# nrf9230_enga_application register map
Vendor: Nordic Semiconductor; Series: nRF92; File version: 1
CPU: CM33 r0p4, little endian, MPU, FPU, 3 interrupt priority bits, 480 interrupts, 4 SAU regions
Registers are 32-bit, read-write, reset 0x0 unless marked. A register's access mark holds for its fields unless they carry their own. Offsets are from the block's base; [hi:lo] are bit positions; lines under a group give offsets from that group; {n}, {i} and the like mark numbered series.

## GLOBAL_FICR_NS — Factory Information Configuration Registers
Base 0x0FFFE000
0x0C BLE group — Unspecified
  0x00 ADDRTYPE ro reset 0xFFFFFFFF — Device address type.
    [0] TYPE
      0=Public address; 1=Random address
  {0x4+4j} ADDR[{j}] (j=0..1) ro reset 0xFFFFFFFF — Description collection: 48 bit device address.
    [31:0] ADDR — Device address [n].
  {0xC+4j} ER[{j}] (j=0..3) ro reset 0xFFFFFFFF — Description collection: Encryption Root.
    [31:0] ER — Encryption root word [n].
  {0x1C+4j} IR[{j}] (j=0..3) ro reset 0xFFFFFFFF — Description collection: Identity Root.
    [31:0] IR — Identity root word [n].
0x50 INFO group — Device info
  0x00 CONFIGID ro reset 0xFFFFFFFF — Configuration identifier
    [15:0] HWID — Identification number for the HW
  0x04 PART ro reset 0xFFFFFFFF — Part code
    [31:0] PART
      0xFFFFFFFF=Unspecified
  0x08 VARIANT ro reset 0xFFFFFFFF — Part Variant, Hardware version and Production configuration
    [31:0] VARIANT — Part Variant, Hardware version and Production configuration, encoded as ASCII
      0xFFFFFFFF=Unspecified
  0x0C PACKAGE ro reset 0xFFFFFFFF — Package option
    [31:0] PACKAGE
      0xFFFFFFFF=Unspecified
  0x10 RAM ro reset 0xFFFFFFFF — RAM variant
    [31:0] RAM
      0xFFFFFFFF=Unspecified
  0x14 MRAM ro reset 0xFFFFFFFF — MRAM variant
    [31:0] MRAM
      0xFFFFFFFF=Unspecified
  0x18 CODEPAGESIZE ro reset 0x1000 — Code memory page size in bytes
    [31:0] CODEPAGESIZE
      0xFFFFFFFF=Unspecified
  0x1C CODESIZE ro reset 0x100 — Code memory size
    [31:0] CODESIZE — Code memory size in number of pages
      0xFFFFFFFF=Unspecified
  0x20 DEVICETYPE ro
    [31:0] DEVICETYPE
      0=Die (Device is an physical DIE); 0xFFFFFFFF=FPGA (Device is an FPGA)
0x80 SIPINFO group — SIP-specific device info
  0x00 PARTNO ro reset 0xFFFFFFFF — SIP part number
  {0x4+j} HWREVISION[{j}] (j=0..3) 8-bit ro reset 0xFF — Description collection: SIP hardware revision, encoded in ASCII, ex B0A or B1A
    [7:0] HWREVISION
  {0x8+j} VARIANT[{j}] (j=0..3) 8-bit ro reset 0xFF — Description collection: SIP VARIANT, encoded in ASCII, ex SIAA, SIBA or SICA
    [7:0] VARIANT
  0x0C PMICVERSION ro
    [31:0] PMICVERSION — PMIC version, incremental code
  {0x10+j} TESTSITE[{j}] (j=0..3) 8-bit ro — Description collection: Test site, in ascii
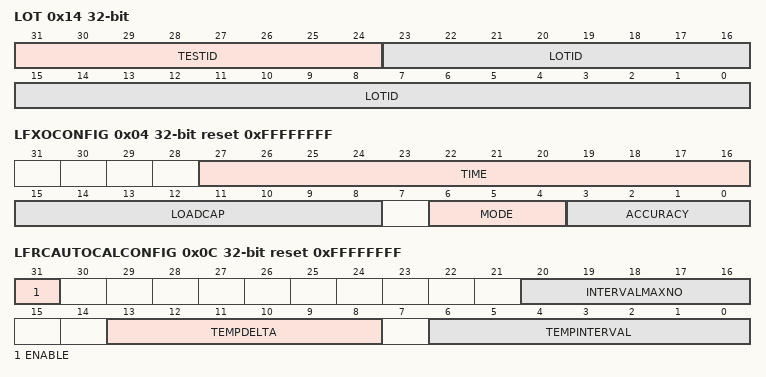
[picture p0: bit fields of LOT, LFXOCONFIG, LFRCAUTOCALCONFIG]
  0x14 LOT ro — Lot number + test index in hex format (number digits 0-9).
    [31:24] TESTID — Test ID in hex format
    [23:0] LOTID — Lot number in hex format
  {0x18+j} TESTPROGRAMID[{j}] (j=0..3) 8-bit ro — Description collection: Test program id, in ascii
  0x1C OSATPARTNO ro reset 0xFFFFFFFF — OSAT part number
  {0x20+j} HWBUILDVERSION[{j}] (j=0..3) 8-bit ro reset 0xFF — Description collection: OSAT production build version
  0x24 OVERRIDE group — Unspecified
    0x00 LFOSC group — Unspecified
      0x00 CONFIG reset 0xFFFFFFFF — LF oscillator configuration. Note. This configuration overrides corresponding LF oscillator configuration in BICR when set.
        [3:0] SRC — LF oscillator source.
          15=Unconfigured (LF oscillator source is unconfigured. Default will be used.); 0=LFXO (Use LFXO as source for the LF oscillator.); 1=LFRC (Use LFRC as source for the LF oscillator.); 2=LFLPRC (Use LFLPRC as source for the LF oscillator.); 3=Synth (Use LF Synth as source for the LF oscillator.)
      0x04 LFXOCONFIG reset 0xFFFFFFFF — LFXO configuration. Note. This configuration overrides corresponding LFXO configuration in BICR when set.
        [27:16] TIME — LFXO startup time in ms.
          0xFFF=Unconfigured (Startup time has not been configured.)
        [15:8] LOADCAP — Built-in load capacitors selection in 1 pF steps. Max. value 25 pF.
          255=Unconfigured (The built-in load capacitors is unconfigured. LFXO will not start unless LOADCAP is configured.); 0=External (Do not use the built-in load capacitors, only external capacitors will be used.)
        [6:4] MODE — LFXO mode. LFXO will not start unless MODE is configured.
          7=Unconfigured (The mode is unconfigured.); 0=Pierce (LFXO Pierce mode.); 1=PIXO (LFXO PIXO mode.); 2=ExtSine (LFXO in external sine wave mode.); 3=ExtSquare (LFXO in external square wave mode.)
        [3:0] ACCURACY — LFXO crystal or external signal accuracy.
          15=Unconfigured (The accuracy is unconfigured.); 0=500ppm (LFXO crystal or external signal has an accuracy of 500 ppm.); 1=250ppm (LFXO crystal or external signal has an accuracy of 250 ppm.); 2=150ppm (LFXO crystal or external signal has an accuracy of 150 ppm.); 3=100ppm (LFXO crystal or external signal has an accuracy of 100 ppm.); 4=75ppm (LFXO crystal or external signal has an accuracy of 75 ppm.); 5=50ppm (LFXO crystal or external signal has an accuracy of 50 ppm.); 6=30ppm (LFXO crystal or external signal has an accuracy of 30 ppm.); 7=20ppm (LFXO crystal or external signal has an accuracy of 20 ppm.)
      0x08 LFXOCAL reset 0xFFFFFFFF — LFXO calibration needed. Must be written to 0xFFFFFFFF after any modification of the LFXO board circuit, load capacitance, or crystal swap. Note. This configuration overrides corresponding LFXO calibration in BICR when set.
        [31:0] LFXOCAL — LFXO calibration needed. Must be written to 0xFFFFFFFF after any modification of the LFXO board circuit, load capacitance, or crystal swap.
          0xFFFFFFFF=Calibrate the LFXO at startup
      0x0C LFRCAUTOCALCONFIG reset 0xFFFFFFFF — LFRC autocalibration configuration. Note. This configuration overrides corresponding LFRC autocalibration configuration in BICR when set.
        [31] ENABLE — LFRC.AUTOCALCONFIG register enable.
          0=Enabled (LFRC.AUTOCALCONFIG register has been configured and can be used.); 1=Disabled (LFRC.AUTOCALCONFIG register has not been configured and cannot be used.)
        [20:16] INTERVALMAXNO — Maximum number of TEMPINTERVAL periods in between calibrations, independent of temperature changes.
        [13:8] TEMPDELTA — Temperature delta that should trigger a calibration in 0.25 degrees steps.
        [6:0] TEMPINTERVAL — Temperature measurement interval in 0.25 s steps.
    0x10 HFXO64M group — Unspecified
      0x00 CONFIG reset 0xFFFFFFFF — HFXO64M configuration. Note. This configuration overrides corresponding XO configuration in BICR when set.
        [2:0] MODE — HFXO64M mode.
          7=Unconfigured (The mode is unconfigured.); 0=Normal operating mode; 1=TCXO (TCXO/bypass mode); {v}=Crystal{v} (Reserved value) (v=2..6)
0x100 TRIM group — Unspecified
  0x244 GLOBAL group — Unspecified
    0x00 SAADC group — Unspecified
      0x00 CALVREF ro reset 0xFFFFFFFF — Trim value for GLOBAL.SAADC.CALVREF
        [31:0] VALUE — Trim value
      {0x4+4l} CALGAIN[{l}] (l=0..2) ro reset 0xFFFFFFFF — Description collection: Trim value for GLOBAL.SAADC.CALGAIN
        [31:0] VALUE — Trim value
      0x10 CALOFFSET ro reset 0xFFFFFFFF — Trim value for GLOBAL.SAADC.CALOFFSET
        [31:0] VALUE — Trim value
      {0x14+4l} LINCALCOEFF[{l}] (l=0..5) ro reset 0xFFFFFFFF — Description collection: Trim value for GLOBAL.SAADC.LINCALCOEFF
        [31:0] VALUE — Trim value
      0x2C CALIREF ro reset 0xFFFFFFFF — Trim value for GLOBAL.SAADC.CALIREF
        [31:0] VALUE — Trim value
      0x30 CALVREFTC ro reset 0xFFFFFFFF — Trim value for GLOBAL.SAADC.CALVREFTC
        [31:0] VALUE — Trim value
    0x3C CANPLL group — Unspecified
      0x00 TRIM group — Unspecified
        0x00 CTUNE ro reset 0xFFFFFFFF — Trim value for GLOBAL.CANPLL.TRIM.CTUNE
          [31:0] VALUE — Trim value
    0x4C COMP group — Unspecified
      0x00 REFTRIM ro reset 0xFFFFFFFF — Trim value for GLOBAL.COMP.REFTRIM
        [31:0] VALUE — Trim value
  0x298 APPLICATION group — Unspecified
    0x00 HSFLL group — Unspecified
      0x00 TRIM group — Unspecified
        0x00 VSUP ro reset 0xFFFFFFFF — Trim value for APPLICATION.HSFLL.TRIM.VSUP
          [31:0] VALUE — Trim value
        {0x4+4m} COARSE[{m}] (m=0..5) ro reset 0xFFFFFFFF — Description collection: Trim value for APPLICATION.HSFLL.TRIM.COARSE
          [31:0] VALUE — Trim value
        {0x1C+4m} FINE[{m}] (m=0..5) ro reset 0xFFFFFFFF — Description collection: Trim value for APPLICATION.HSFLL.TRIM.FINE
          [31:0] VALUE — Trim value
    0x34 MEMCONF group — Unspecified
      {0x0+4l} BLOCKTYPE[{l}] (l=0..3) group — Unspecified
        0x00 TRIM ro reset 0xFFFFFFFF — Description cluster: Trim value for APPLICATION.MEMCONF.BLOCKTYPE[n].TRIM
          [31:0] VALUE — Trim value
  0x2DC RADIOCORE group — Unspecified
    0x00 HSFLL group — Unspecified
      0x00 TRIM group — Unspecified
        0x00 VSUP ro reset 0xFFFFFFFF — Trim value for RADIOCORE.HSFLL.TRIM.VSUP
          [31:0] VALUE — Trim value
        {0x4+4m} COARSE[{m}] (m=0..5) ro reset 0xFFFFFFFF — Description collection: Trim value for RADIOCORE.HSFLL.TRIM.COARSE
          [31:0] VALUE — Trim value
        {0x1C+4m} FINE[{m}] (m=0..5) ro reset 0xFFFFFFFF — Description collection: Trim value for RADIOCORE.HSFLL.TRIM.FINE
          [31:0] VALUE — Trim value
    0x34 MEMCONF group — Unspecified
      {0x0+4l} BLOCKTYPE[{l}] (l=0..3) group — Unspecified
        0x00 TRIM ro reset 0xFFFFFFFF — Description cluster: Trim value for RADIOCORE.MEMCONF.BLOCKTYPE[n].TRIM
          [31:0] VALUE — Trim value

## Notices in the file
Copyright (c) 2010 - 2024, Nordic Semiconductor ASA All rights reserved.
SPDX-License-Identifier: BSD-3-Clause
Redistribution and use in source and binary forms, with or without
modification, are permitted provided that the following conditions are met:
1. Redistributions of source code must retain the above copyright notice, this
list of conditions and the following disclaimer.
2. Redistributions in binary form must reproduce the above copyright
notice, this list of conditions and the following disclaimer in the
documentation and/or other materials provided with the distribution.
3. Neither the name of Nordic Semiconductor ASA nor the names of its
contributors may be used to endorse or promote products derived from this
software without specific prior written permission.
THIS SOFTWARE IS PROVIDED BY THE COPYRIGHT HOLDERS AND CONTRIBUTORS "AS IS"
AND ANY EXPRESS OR IMPLIED WARRANTIES, INCLUDING, BUT NOT LIMITED TO, THE
IMPLIED WARRANTIES OF MERCHANTABILITY, AND FITNESS FOR A PARTICULAR PURPOSE
ARE DISCLAIMED. IN NO EVENT SHALL NORDIC SEMICONDUCTOR ASA OR CONTRIBUTORS BE
LIABLE FOR ANY DIRECT, INDIRECT, INCIDENTAL, SPECIAL, EXEMPLARY, OR
CONSEQUENTIAL DAMAGES (INCLUDING, BUT NOT LIMITED TO, PROCUREMENT OF
SUBSTITUTE GOODS OR SERVICES; LOSS OF USE, DATA, OR PROFITS; OR BUSINESS
INTERRUPTION) HOWEVER CAUSED AND ON ANY THEORY OF LIABILITY, WHETHER IN
CONTRACT, STRICT LIABILITY, OR TORT (INCLUDING NEGLIGENCE OR OTHERWISE)
ARISING IN ANY WAY OUT OF THE USE OF THIS SOFTWARE, EVEN IF ADVISED OF THE
POSSIBILITY OF SUCH DAMAGE.
